# A31C14x register map
Vendor: ABOV Semiconductor Co., Ltd.; File version: 1.0
CPU: CM0PLUS r0p1, little endian, no MPU, no FPU, VTOR, 2 interrupt priority bits
Registers are 32-bit, read-write, reset 0x0 unless marked. A register's access mark holds for its fields unless they carry their own. Offsets are from the block's base; [hi:lo] are bit positions; {n}, {i} and the like mark numbered series.

## FRT — Free Run Timer
Base 0x40000600
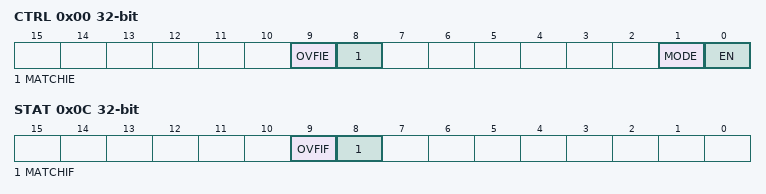
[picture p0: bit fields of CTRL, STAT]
0x00 CTRL — FRT control register
  [9] OVFIE — Whether to enable or disable the FRT counter overflow interrupt in Free-run timer mode (MODE = 0)
    0=Disable (Interrupt Disable); 1=Enable (Interrupt Enable)
  [8] MATCHIE — Whether to enable or disable the FRT counter match interrupt in Periodic timer mode (MODE = 1)
    0=Disable (Interrupt Disable); 1=Enable (Interrupt Enable)
  [1] MODE — FRT mode selection
    0=Free-Run_Timer; 1=Periodic_Timer
  [0] EN — Whether to enable or disable the FRT
    0=Disable (FRT Disable); 1=Enable (FRT Enable)
0x04 MCNT reset 0xFFFFFFFF — FRT match counter register
  [31:0] MCNT — FRTs match counter value
0x08 CNT — FRT counter register
  [31:0] CNT — FRT count data
0x0C STAT — FRT status register
  [9] OVFIF — FRT counter overflow interrupt flag
  [8] MATCHIF — FRT counter match interrupt flag

## UART0 — Universal Asynchronous Receiver/Transmitter 0
Base 0x40008000
Same registers: UART1 0x40008100
0x00 RBR ro — UART n receive data buffer register
  [7:0] RBR — Receive buffer register
0x00 THR wo — UART n transmit data hold register
  [7:0] THR — Transmit data hold register
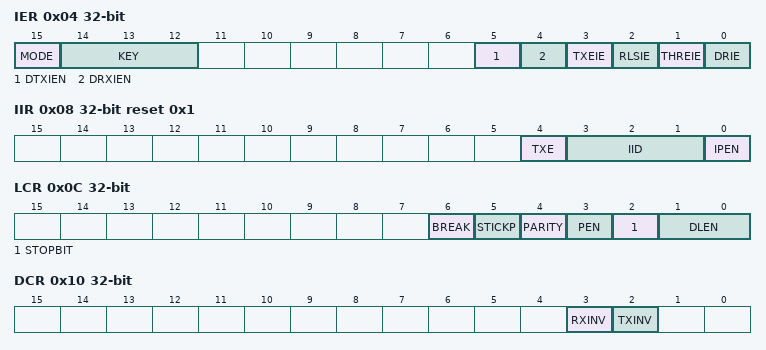
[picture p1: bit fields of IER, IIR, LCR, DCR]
0x04 IER — UART n interrupt enable register
  [15] MODE — Enable or disable IIR extended mode bit
    0=legacy (IIR legacy mode); 1=extended (IIR extended mode)
  [14:12] KEY — Mode change key (0x05)
  [5] DTXIEN — Whether to enable or disable the DMA transmit complete interrupt
  [4] DRXIEN — Whether to enable or disable the DMA receive complete interrupt
  [3] TXEIE — Whether to enable or disable the transmit complete interrupt
  [2] RLSIE — Whether to enable or disable the receive line status interrupt
  [1] THREIE — Whether to enable or disable the transmit data hold register empty (THRE) interrupt
  [0] DRIE — Whether to enable or disable the data receive interrupt
0x08 IIR ro reset 0x1 — UART n interrupt ID register
  [4] TXE — Transmit complete
  [3:1] IID — Interrupt source ID
  [0] IPEN — Presence of pending interrupts
0x0C LCR — UART n line control register
  [6] BREAK — When this bit is set to 1, the TXD pin is driven low to alert the receiver
  [5] STICKP — Whether or not to use stick parity. The setting of this bit is valid only when the PEN bit is set to 1
  [4] PARITY — Parity mode selection
  [3] PEN — Whether or not to enable parity
  [2] STOPBIT — The number of stop bits demanded by the preceding data bits
  [1:0] DLEN — The length of data bits included by each data transfer
    {v}={v+5}bit data (v=0..3)
0x10 DCR — UART n data control register
  [3] RXINV — Rx data inversion selection
  [2] TXINV — Tx data inversion selection
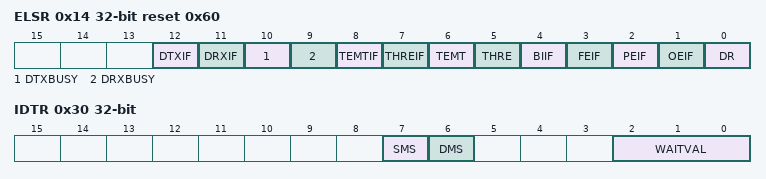
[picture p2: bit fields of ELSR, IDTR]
0x14 ELSR reset 0x60 — UART n line status register
  [12] DTXIF — DMA Transmit complete interrupt flag
  [11] DRXIF — DMA Receiver complete interrupt flag
  [10] DTXBUSY ro — DMA transmit busy check (DTXBUSY indicates whether or not the DMA transmit data is busy)
  [9] DRXBUSY ro — DMA receive busy check (DRXBUSY indicates whether or not the DMA receive data is busy)
  [8] TEMTIF — Transmit complete interrupt flag
  [7] THREIF — Transmit data hold register empty flag
  [6] TEMT ro — Indicates the transmit registers are empty
  [5] THRE ro — Indicates the transmit data hold register is empty
  [4] BIIF — Indicates a break condition has been detected flag
  [3] FEIF — Indicates presence of a frame error flag
  [2] PEIF — Indicates presence of a parity error flag
  [1] OEIF — Indicates presence of an overrun error flag
  [0] DR ro — Indicates data reception status
0x20 BDR — UART n baud-rate divisor latch register
  [15:0] BDR — Baud-rate divisor latch (1 to 65535)
0x24 BFR — UART n baud-rate fraction counter register
  [7:0] BFR — Whether to enable or disable the fraction counter to compensate error from the integer baud-rate divisor
0x30 IDTR — UARTn Inter-frame Delay Time Register
  [7] SMS — Whether to enable or disable multi-sampling the start bit
  [6] DMS — Whether to enable or disable multi-sampling each data bit
  [2:0] WAITVAL — Defines the wait time for the next data frame. [unit: 1-bit period]
